# EFR32MG22C224F512GN32 register map
Vendor: Silicon Labs; Series: EFR32; File version: C
Registers are 32-bit, read-write, reset 0x0 unless marked. A register's access mark holds for its fields unless they carry their own. Offsets are from the block's base; [hi:lo] are bit positions; 'fields as' and 'values as' point back to an identical list.

## RADIOAES_S — RADIOAES_S Registers
Base 0x44000000
Same registers: RADIOAES_NS 0x54000000
0x00 FETCHADDR — Fetcher: Start address of data block. In direct mode, this register is written by the software. In scatter-gather mode, this register is updated after each processed descriptor.
  [31:0] ADDR — Start address of data block
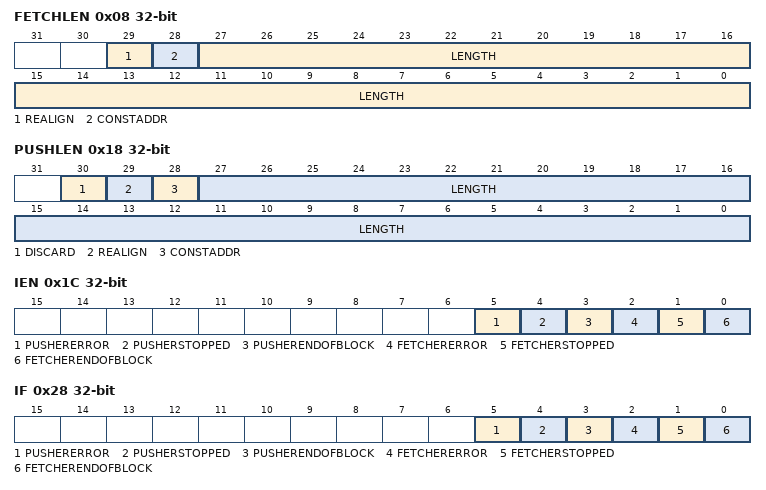
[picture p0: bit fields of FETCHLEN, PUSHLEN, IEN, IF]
0x08 FETCHLEN — Fetcher: Length of data block. In direct mode, this register is written by the software. In scatter-gather mode, this register is not used.
  [29] REALIGN — Realign lengh
  [28] CONSTADDR — Constant address
  [27:0] LENGTH — Length of data block
0x0C FETCHTAG — Fetcher: User tag. In direct mode, this register is written by the software. In scatter-gather mode, this register is not used.
  [31:0] TAG — User tag
0x10 PUSHADDR — Pusher: Start address of data block (LSB). In direct mode, this register is written by the software. In scatter-gather mode, this register is updated after each processed descriptor.
  [31:0] ADDR — Start address of data block
0x18 PUSHLEN — Pusher: Length of data block. In direct mode, this register is written by the software. In scatter-gather mode, this register is not used.
  [30] DISCARD — Discard data
  [29] REALIGN — Realign length
  [28] CONSTADDR — Constant address
  [27:0] LENGTH — Start address of data block
0x1C IEN — Interrupt enable
  [5] PUSHERERROR — Error interrupt enable
  [4] PUSHERSTOPPED — Stopped interrupt enable
  [3] PUSHERENDOFBLOCK — End of block interrupt enable
  [2] FETCHERERROR — Error interrupt enable
  [1] FETCHERSTOPPED — Stopped interrupt enable
  [0] FETCHERENDOFBLOCK — End of block interrupt enable
0x28 IF ro — Interrupt flag register
  [5] PUSHERERROR — Error interrupt flag
  [4] PUSHERSTOPPED — Stopped interrupt flag
  [3] PUSHERENDOFBLOCK — End of block interrupt flag
  [2] FETCHERERROR — Error interrupt flag
  [1] FETCHERSTOPPED — Stopped interrupt flag
  [0] FETCHERENDOFBLOCK — End of block interrupt flag
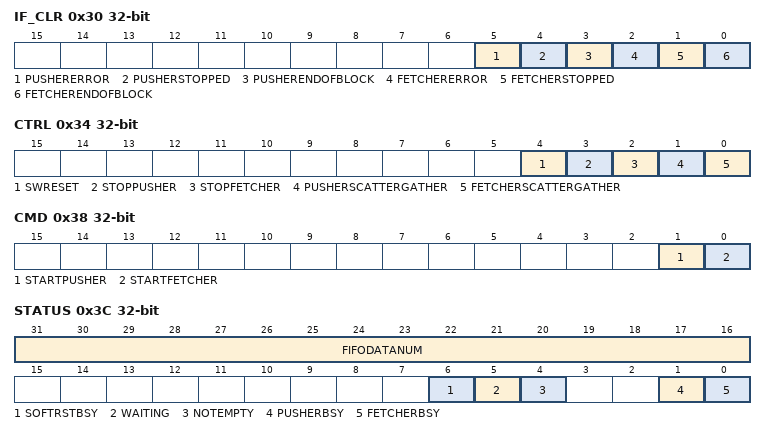
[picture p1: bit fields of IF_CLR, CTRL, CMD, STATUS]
0x30 IF_CLR wo — Writing a '1' clears the interrupt status. Writing a '0' has no effect.
  [5] PUSHERERROR — FETCHERERRORIFC
  [4] PUSHERSTOPPED — FETCHERSTOPPEDIFC
  [3] PUSHERENDOFBLOCK — FETCHERENDOFBLOCKIFC
  [2] FETCHERERROR — Error interrupt flag clear
  [1] FETCHERSTOPPED — Stopped interrupt flag clear
  [0] FETCHERENDOFBLOCK — End of block interrupt flag clear
0x34 CTRL — Control register, called CONFIG in Barco datasheet.
  [4] SWRESET — Software reset
  [3] STOPPUSHER
  [2] STOPFETCHER
  [1] PUSHERSCATTERGATHER
  [0] FETCHERSCATTERGATHER
0x38 CMD wo — Command register for starting the fetcher and pusher
  [1] STARTPUSHER — Start push
  [0] STARTFETCHER — Start fetch
0x3C STATUS ro
  [31:16] FIFODATANUM — Number of data in output FIFO
  [6] SOFTRSTBSY — Software reset busy
  [5] WAITING — Pusher waiting for FIFO
  [4] NOTEMPTY — Not empty flag from input FIFO (fetcher)
  [1] PUSHERBSY — Pusher busy
  [0] FETCHERBSY — Fetcher busy
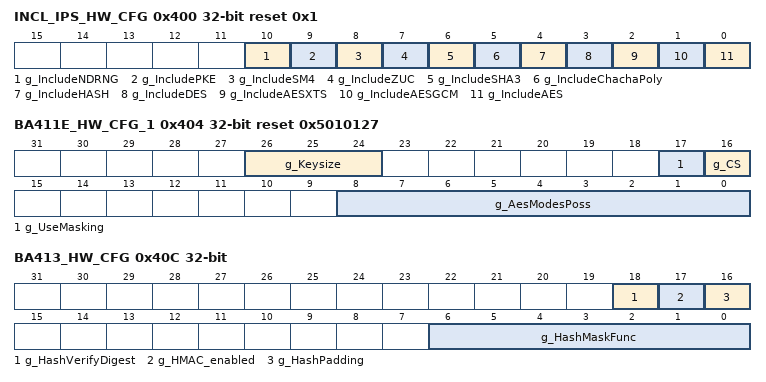
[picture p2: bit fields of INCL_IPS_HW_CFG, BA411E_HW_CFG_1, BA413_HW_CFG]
0x400 INCL_IPS_HW_CFG ro reset 0x1
  [10] g_IncludeNDRNG — Generic g_IncludeNDRNG value
  [9] g_IncludePKE — Generic g_IncludePKE value
  [8] g_IncludeSM4 — Generic g_IncludeSM4 value
  [7] g_IncludeZUC — Generic g_IncludeZUC value
  [6] g_IncludeSHA3 — Generic g_IncludeSHA3 value
  [5] g_IncludeChachaPoly — Generic g_IncludeChachaPoly value
  [4] g_IncludeHASH — Generic g_IncludeHASH value
  [3] g_IncludeDES — Generic g_IncludeDES value
  [2] g_IncludeAESXTS — Generic g_IncludeAESXTS value
  [1] g_IncludeAESGCM — Generic g_IncludeAESGCM value
  [0] g_IncludeAES — Generic g_IncludeAES value
0x404 BA411E_HW_CFG_1 ro reset 0x5010127
  [26:24] g_Keysize — Generic g_Keysize value
  [17] g_UseMasking — Generic g_UseMasking value
  [16] g_CS — Generic g_CS value
  [8:0] g_AesModesPoss — AES Modes Supported
0x408 BA411E_HW_CFG_2 ro reset 0x80
  [15:0] g_CtrSize — Generic g_CtrSize value
0x40C BA413_HW_CFG ro
  [18] g_HashVerifyDigest — Generic g_HashVerifyDigest value
  [17] g_HMAC_enabled — Generic g_HMAC_enabled value
  [16] g_HashPadding — Generic g_HashPadding value
  [6:0] g_HashMaskFunc — Generic g_HashMaskFunc value
0x410 BA418_HW_CFG ro reset 0x1
  [0] g_Sha3CtxtEn — Generic g_Sha3CtxtEn value
0x414 BA419_HW_CFG ro
  [6:0] g_SM4ModesPoss — Generic g_SM4ModesPoss value

## CRYPTOACC_S — CRYPTOACC_S Registers
Base 0x4C020000
Same registers: CRYPTOACC_NS 0x5C020000
Registers as RADIOAES_S; these are added or differ:
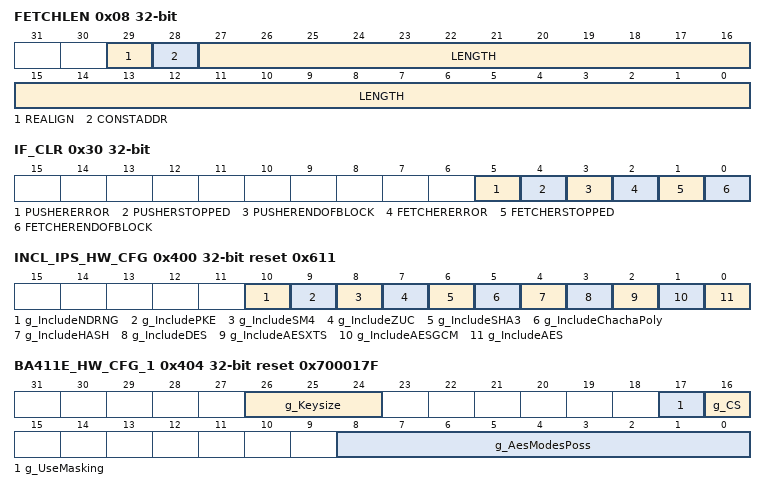
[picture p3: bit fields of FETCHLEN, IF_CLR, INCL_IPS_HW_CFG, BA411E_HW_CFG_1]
0x08 FETCHLEN — Fetcher: Length of data block. In direct mode, this register is written by the software. In scatter-gather mode, this register is not used.
  [29] REALIGN — Realign length
  [28] CONSTADDR — Constant address
  [27:0] LENGTH — Length of data block
0x30 IF_CLR wo — Writing a '1' clears the interrupt status. Writing a '0' has no effect.
  [5] PUSHERERROR — Error interrupt flag clear
  [4] PUSHERSTOPPED — Stopped interrupt flag clear
  [3] PUSHERENDOFBLOCK — End of block interrupt flag clear
  [2] FETCHERERROR — Error interrupt flag clear
  [1] FETCHERSTOPPED — Stopped interrupt flag clear
  [0] FETCHERENDOFBLOCK — End of block interrupt flag clear
0x400 INCL_IPS_HW_CFG ro reset 0x611
  fields as RADIOAES_S.INCL_IPS_HW_CFG
0x404 BA411E_HW_CFG_1 ro reset 0x700017F
  [26:24] g_Keysize — Generic g_Keysize value
  [17] g_UseMasking — Generic g_UseMasking value
  [16] g_CS — Generic g_CS value
  [8:0] g_AesModesPoss — AES Modes Supported
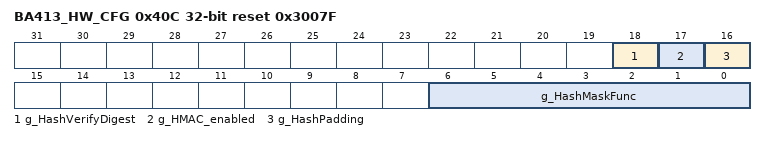
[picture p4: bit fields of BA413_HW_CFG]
0x40C BA413_HW_CFG ro reset 0x3007F
  fields as RADIOAES_S.BA413_HW_CFG
0x414 BA419_HW_CFG ro reset 0x5F
  [6:0] g_SM4ModesPoss — Generic g_SM4ModesPoss value
